VERSION ""

NS_ :

BS_:

BU_: XXX

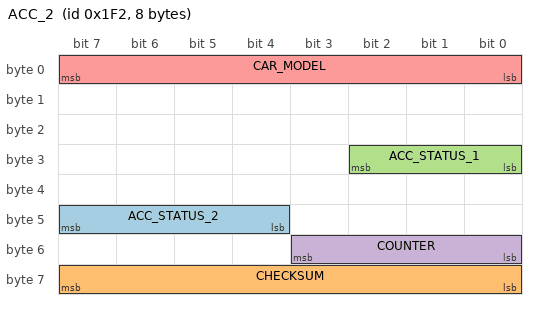
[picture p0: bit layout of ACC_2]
BO_ 498 ACC_2: 8 XXX
 SG_ ACC_STATUS_2 : 47|4@0+ (1,0) [0|1] "" XXX
 SG_ CHECKSUM : 63|8@0+ (1,0) [0|1] "" XXX
 SG_ ACC_STATUS_1 : 26|3@0+ (1,0) [0|1] "" XXX
 SG_ COUNTER : 51|4@0+ (1,0) [0|1] "" XXX
 SG_ CAR_MODEL : 7|8@0+ (1,0) [0|1] "" XXX

CM_ SG_ 498 ACC_STATUS_2 "1 no ACC, 3 icpno ";
CM_ SG_ 498 ACC_STATUS_1 "0x00 = acc off, 0x03 = acc on, green, 0x02 acc on, white";
